# MIK32 register map
Vendor: Mikron; Series: MIK32; File version: 1.0
Registers are 32-bit, read-write, reset 0x0 unless marked. A register's access mark holds for its fields unless they carry their own. Offsets are from the block's base; [hi:lo] are bit positions; {n}, {i} and the like mark numbered series.

## TIMER32_2 — регистры модуля таймера_2
Base 0x00082C00
0x00 TIM2_VALUE ro
  [31:0] TIM_VAL — текущее значение счетчика
0x04 TIM2_TOP reset 0xFFFFFFFF — максимальное значение счетной последовательности
  [31:0] TIM_TOP — максимальное значение счетчика (ограничивает счетную последоваельность сверху)
0x08 TIM2_PRESCALE — значение делителя
  [31:0] TIM_PRESCALE — Значение предварительного делителя. Предделитель вырабатывает тактовый сигнал для счета, частота которого в (TIM_PRESCALE + 1) раз меньше входной. Диапазон значений от 0 до (232 - 1)
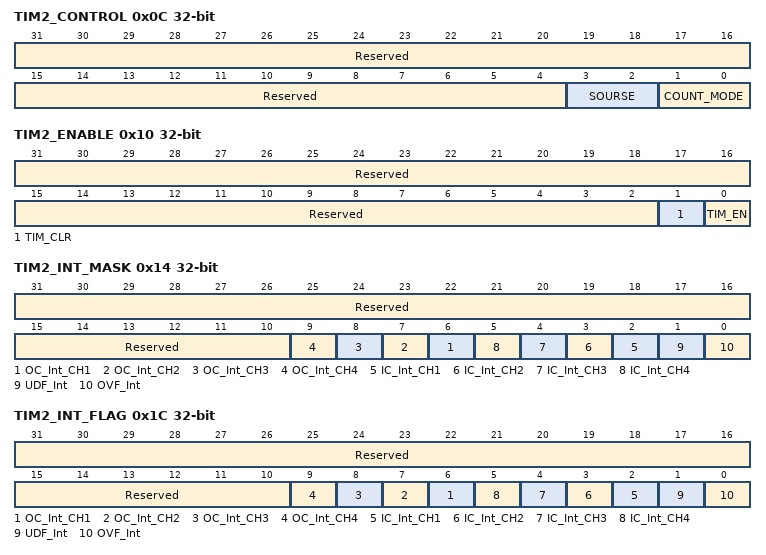
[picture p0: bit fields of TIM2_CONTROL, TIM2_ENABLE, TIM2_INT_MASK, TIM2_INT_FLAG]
0x0C TIM2_CONTROL reset not defined — Конфигурационный регистр основного таймера
  [31:4] Reserved — Зарезервировано
  [3:2] SOURSE — Выбор источника тактового сигнала для счета
    0=TIM1 (Вход модуля TIM1); 2=TIM2 (Вход модуля TIM2); 3=TIM3 (Выход предделителя)
  [1:0] COUNT_MODE — Режим счёта таймера
    0=Direct (Прямой режим); 1=Reverse (Обратный режим); 2=Bidirectional (Двунаправленный режим)
0x10 TIM2_ENABLE — Регистр включения таймера
  [31:2] Reserved — Зарезервировано
  [1] TIM_CLR write-once — Сброс (обнуление) текущего значения счетчика при записи «1»
  [0] TIM_EN — Запуск/остановка работы счетчика
    0=Disable (Счетчик выключен); 1=Enable (Счетчик работает)
0x14 TIM2_INT_MASK — Регистр маски прерываний
  [31:10] Reserved — Зарезервировано
  [n+5] OC_Int_CH{n} (n=1..4) — Маска прерывания совпадения {n} канала таймера
  [n+1] IC_Int_CH{n} (n=1..4) — Маска прерывания захвата {n} канала таймера
  [1] UDF_Int — Маска прерывания опустошения счетчика
  [0] OVF_Int — Маска прерывания по переполнению счетчика
0x18 TIM2_INT_CLEAR reset 0xFFFFFFFF — Регистр сброса флагов прерываний
0x1C TIM2_INT_FLAG ro — Регистр флагов прерываний
  [31:10] Reserved — Зарезервировано
  [n+5] OC_Int_CH{n} (n=1..4) — Статус прерывания совпадения {n} канала таймера
  [n+1] IC_Int_CH{n} (n=1..4) — Статус прерывания захвата {n} канала таймера
  [1] UDF_Int — Статус прерывания опустошения счетчика
  [0] OVF_Int — Статус прерывания по переполнению счетчика
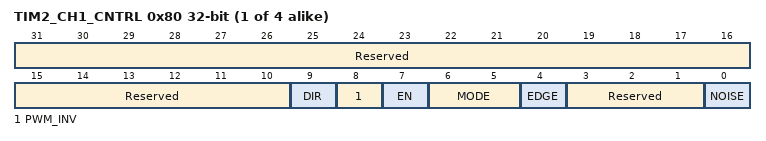
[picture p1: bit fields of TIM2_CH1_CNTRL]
{0x70+0x10*i} TIM2_CH{i}_CNTRL (i=1..4) — Конфигурационный регистр {i} канала
  [31:10] Reserved — Зарезервировано
  [9] DIR ro — Направление передачи данных. Устанавливается автоматически в зависимости от режима работы (1 - выход, 0 - вход)
    1=Output (Выход); 0=Input (Вход)
  [8] PWM_INV — Тип вывода в режиме ШИМ инвертирование
    0=Direct (Прямой (не инвертированный) выход); 1=Inverted (Инвертированный выход)
  [7] EN — Включение/выключение канала
  [6:5] MODE — Режим работы канала
    0=Reserved (Зарезервировано); 1=Compare (Режим сравнения (для timer0)); 2=Capture (Режим захвата(для timer0)); 3=PWM (ШИМ)
  [4] EDGE — Режим сигнала захвата
    0=Front (фронт); 1=Back (срез)
  [3:1] Reserved — Зарезервировано
  [0] NOISE — Управление фильтрацией входных помех на входе ic_port: 0 – фильтрация выклю-чена; 1 – фильтрация выклю-чена
    0=Enable (Фильтрация выключена); 1=Disable (Фильтрация включена)
{0x74+0x10*i} TIM2_CH{i}_OCR (i=1..4) — Значение сравнения {i} канала
  [31:0] OCR — Значение таймера в режиме сравнения
{0x78+0x10*i} TIM2_CH{i}_ICR (i=1..4) — Значение захвата {i} канала
  [31:0] ICR — Значение таймера в режиме захвата

## GPIO0 — Модуль ввода/вывода
Base 0x00084000
Same registers: GPIO1 0x00084400
0x00 STATE ro — Установка выводов в «1»
0x00 SET wo — Текущее состояние выводов
0x04 CLEAR wo — Текущее состояние прерываний / Установка «0» При чтении – текущее состояние запросов прерываний. При записи бита «1» соответствующий биту вывод устанавливается в «0»
0x08 DIRECTION_OUT reset 0xFFFF — Установка направления выводов как выход При чтении – текущее направление выводов: 0 – выход; 1 – вход. Запись «1» устанавливает соответствующий вывод как «выход»
0x0C DIRECTION_IN reset 0xFFFF — Установка направления выводов как вход При чтении – текущее направление выводов: 0 – выход; 1 – вход. Запись «1» устанавливает соответствующий вывод как «вход»
0x10 OUTPUT — Выходной регистр Чтение возвращает содержимое выходного регистра независимо от текущего направления выводов Запись устанавливает значения всех битов выходного регистра
0x14 CONTROL — Тестовый режим Запись «1» в [0:0] разряд – включение тестового режима (выходы замкнуты на входы внутри модуля) Запись «0» в [0:0] разряд – нормальный режим

## GPIO2 — Модуль ввода/вывода
Base 0x00084800
Registers as GPIO0; these are added or differ:
0x08 DIRECTION_OUT reset 0xFF — Установка направления выводов как выход При чтении – текущее направление выводов: 0 – выход; 1 – вход. Запись «1» устанавливает соответствующий вывод как «выход»
0x0C DIRECTION_IN reset 0xFF — Установка направления выводов как вход При чтении – текущее направление выводов: 0 – выход; 1 – вход. Запись «1» устанавливает соответствующий вывод как «вход»
